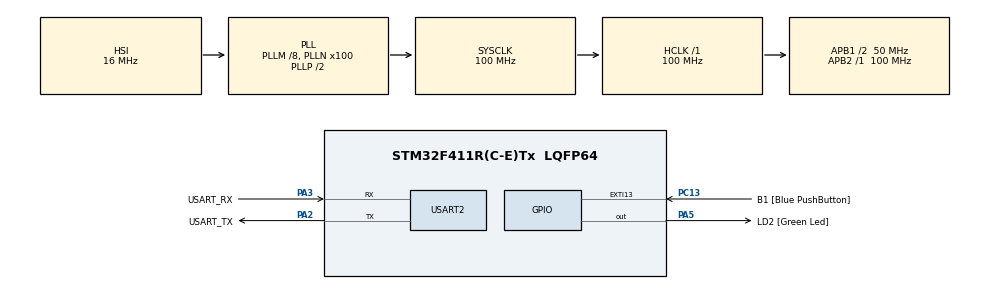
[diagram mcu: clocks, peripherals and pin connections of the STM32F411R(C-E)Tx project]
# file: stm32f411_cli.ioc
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ADC1.Channel-0\#ChannelRegularConversion=ADC_CHANNEL_TEMPSENSOR
ADC1.ContinuousConvMode=ENABLE
ADC1.DMAContinuousRequests=ENABLE
ADC1.InjNumberOfConversion=0
ADC1.NbrOfConversion=1
ADC1.NbrOfConversionFlag=1
ADC1.Rank-0\#ChannelRegularConversion=1
ADC1.SamplingTime-0\#ChannelRegularConversion=ADC_SAMPLETIME_480CYCLES
ADC1.ScanConvMode=ENABLE
ADC1.master=1
Dma.ADC1.0.Direction=DMA_PERIPH_TO_MEMORY
Dma.ADC1.0.FIFOMode=DMA_FIFOMODE_DISABLE
Dma.ADC1.0.Instance=DMA2_Stream0
Dma.ADC1.0.MemDataAlignment=DMA_MDATAALIGN_HALFWORD
Dma.ADC1.0.MemInc=DMA_MINC_ENABLE
Dma.ADC1.0.Mode=DMA_CIRCULAR
Dma.ADC1.0.PeriphDataAlignment=DMA_PDATAALIGN_HALFWORD
Dma.ADC1.0.PeriphInc=DMA_PINC_DISABLE
Dma.ADC1.0.Priority=DMA_PRIORITY_LOW
Dma.Request0=ADC1
FREERTOS.Tasks01=defaultTask,24,512,StartDefaultTask,As weak,NULL,Dynamic,NULL,NULL;myTask02,8,256,ledSystemTask,As weak,NULL,Dynamic,NULL,NULL;myTask03,8,256,tempSystemTask,As weak,NULL,Dynamic,NULL,NULL;myTask04,8,512,monitorSystemTask,As weak,NULL,Dynamic,NULL,NULL
Mcu.Family=STM32F4
Mcu.Name=STM32F411R(C-E)Tx
Mcu.Package=LQFP64
NVIC.DMA2_Stream0_IRQn=true\:5\:0\:false\:false\:true\:true\:false\:true\:true
NVIC.EXTI15_10_IRQn=true\:5\:0\:false\:false\:true\:true\:true\:true\:true
NVIC.PriorityGroup=NVIC_PRIORITYGROUP_4
NVIC.TIM1_UP_TIM10_IRQn=true\:15\:0\:false\:false\:true\:false\:false\:true\:true
NVIC.TimeBase=TIM1_UP_TIM10_IRQn
NVIC.TimeBaseIP=TIM10
NVIC.USART2_IRQn=true\:5\:0\:false\:false\:true\:true\:true\:true\:true
PA13.GPIO_Label=TMS
PA13.Mode=Serial_Wire
PA13.Signal=SYS_JTMS-SWDIO
PA14.GPIO_Label=TCK
PA14.Mode=Serial_Wire
PA14.Signal=SYS_JTCK-SWCLK
PA2.GPIO_Label=USART_TX
PA2.Mode=Asynchronous
PA2.Signal=USART2_TX
PA3.GPIO_Label=USART_RX
PA3.Mode=Asynchronous
PA3.Signal=USART2_RX
PA5.GPIO_Label=LD2 [Green Led]
PA5.Signal=GPIO_Output
PB3.GPIO_Label=SWO
PB3.Signal=SYS_JTDO-SWO
PC13-ANTI_TAMP.GPIO_Label=B1 [Blue PushButton]
PC13-ANTI_TAMP.GPIO_ModeDefaultEXTI=GPIO_MODE_IT_FALLING
PC13-ANTI_TAMP.Signal=GPXTI13
PC14-OSC32_IN.Mode=LSE-External-Oscillator
PC14-OSC32_IN.Signal=RCC_OSC32_IN
PC15-OSC32_OUT.Mode=LSE-External-Oscillator
PC15-OSC32_OUT.Signal=RCC_OSC32_OUT
PH0\ -\ OSC_IN.Mode=HSE-External-Clock-Source
PH0\ -\ OSC_IN.Signal=RCC_OSC_IN
PH1\ -\ OSC_OUT.Mode=HSE-External-Clock-Source
PH1\ -\ OSC_OUT.Signal=RCC_OSC_OUT
ProjectManager.HeapSize=0x200
ProjectManager.StackSize=0x400
ProjectManager.TargetToolchain=CMake
RCC.48MHZClocksFreq_Value=50000000
RCC.AHBFreq_Value=100000000
RCC.APB1CLKDivider=RCC_HCLK_DIV2
RCC.APB1Freq_Value=50000000
RCC.APB1TimFreq_Value=100000000
RCC.APB2Freq_Value=100000000
RCC.APB2TimFreq_Value=100000000
RCC.CortexFreq_Value=100000000
RCC.FLatency-AdvancedSettings=FLASH_LATENCY_3
RCC.HCLKFreq_Value=100000000
RCC.HSE_VALUE=8000000
RCC.HSI_VALUE=16000000
RCC.PLLM=8
RCC.PLLN=100
RCC.SYSCLKFreq_VALUE=100000000
RCC.SYSCLKSource=RCC_SYSCLKSOURCE_PLLCLK
RCC.VCOOutputFreq_Value=200000000
USART2.VirtualMode=VM_ASYNC
VP_ADC1_TempSens_Input.Mode=IN-TempSens
VP_ADC1_Vref_Input.Mode=IN-Vrefint
VP_FREERTOS_VS_CMSIS_V2.Mode=CMSIS_V2
VP_SYS_VS_tim10.Mode=TIM10
board=NUCLEO-F411RE

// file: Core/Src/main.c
/* USER CODE BEGIN Header */
/**
  ******************************************************************************
  * @file           : main.c
  * @brief          : Main program body
  ******************************************************************************
  * @attention
  *
  * Copyright (c) 2026 STMicroelectronics.
  * All rights reserved.
  *
  * This software is licensed under terms that can be found in the LICENSE file
  * in the root directory of this software component.
  * If no LICENSE file comes with this software, it is provided AS-IS.
  *
  ******************************************************************************
  */
/* USER CODE END Header */
#include "main.h"
#include "cmsis_os.h"
#include "adc.h"
#include "dma.h"
#include "usart.h"
#include "gpio.h"

void SystemClock_Config(void);
void MX_FREERTOS_Init(void);

int main(void)
{

  /* MCU Configuration--------------------------------------------------------*/

  /* Reset of all peripherals, Initializes the Flash interface and the Systick. */
  HAL_Init();

  /* Configure the system clock */
  SystemClock_Config();

  /* Initialize all configured peripherals */
  MX_GPIO_Init();
  MX_DMA_Init();
  MX_USART2_UART_Init();
  MX_ADC1_Init();

  /* Init scheduler */
  osKernelInitialize();  /* Call init function for freertos objects (in cmsis_os2.c) */
  MX_FREERTOS_Init();

  /* Start scheduler */
  osKernelStart();

  /* We should never get here as control is now taken by the scheduler */

  /* Infinite loop */
  while (1)
  {

  }
}

void SystemClock_Config(void)
{
  RCC_OscInitTypeDef RCC_OscInitStruct = {0};
  RCC_ClkInitTypeDef RCC_ClkInitStruct = {0};

  /** Configure the main internal regulator output voltage
  */
  __HAL_RCC_PWR_CLK_ENABLE();
  __HAL_PWR_VOLTAGESCALING_CONFIG(PWR_REGULATOR_VOLTAGE_SCALE1);

  /** Initializes the RCC Oscillators according to the specified parameters
  * in the RCC_OscInitTypeDef structure.
  */
  RCC_OscInitStruct.OscillatorType = RCC_OSCILLATORTYPE_HSI;
  RCC_OscInitStruct.HSIState = RCC_HSI_ON;
  RCC_OscInitStruct.HSICalibrationValue = RCC_HSICALIBRATION_DEFAULT;
  RCC_OscInitStruct.PLL.PLLState = RCC_PLL_ON;
  RCC_OscInitStruct.PLL.PLLSource = RCC_PLLSOURCE_HSI;
  RCC_OscInitStruct.PLL.PLLM = 8;
  RCC_OscInitStruct.PLL.PLLN = 100;
  RCC_OscInitStruct.PLL.PLLP = RCC_PLLP_DIV2;
  RCC_OscInitStruct.PLL.PLLQ = 4;
  if (HAL_RCC_OscConfig(&RCC_OscInitStruct) != HAL_OK)
  {
    Error_Handler();
  }

  /** Initializes the CPU, AHB and APB buses clocks
  */
  RCC_ClkInitStruct.ClockType = RCC_CLOCKTYPE_HCLK|RCC_CLOCKTYPE_SYSCLK
                              |RCC_CLOCKTYPE_PCLK1|RCC_CLOCKTYPE_PCLK2;
  RCC_ClkInitStruct.SYSCLKSource = RCC_SYSCLKSOURCE_PLLCLK;
  RCC_ClkInitStruct.AHBCLKDivider = RCC_SYSCLK_DIV1;
  RCC_ClkInitStruct.APB1CLKDivider = RCC_HCLK_DIV2;
  RCC_ClkInitStruct.APB2CLKDivider = RCC_HCLK_DIV1;

  if (HAL_RCC_ClockConfig(&RCC_ClkInitStruct, FLASH_LATENCY_3) != HAL_OK)
  {
    Error_Handler();
  }
}

void HAL_TIM_PeriodElapsedCallback(TIM_HandleTypeDef *htim)
{
  if (htim->Instance == TIM10)
  {
    HAL_IncTick();
  }
}

void Error_Handler(void)
{
  __disable_irq();
  while (1)
  {
  }
}

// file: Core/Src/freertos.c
/* USER CODE BEGIN Header */
/**
  ******************************************************************************
  * File Name          : freertos.c
  * Description        : Code for freertos applications
  ******************************************************************************
  * @attention
  *
  * Copyright (c) 2026 STMicroelectronics.
  * All rights reserved.
  *
  * This software is licensed under terms that can be found in the LICENSE file
  * in the root directory of this software component.
  * If no LICENSE file comes with this software, it is provided AS-IS.
  *
  ******************************************************************************
  */
/* USER CODE END Header */

#include "FreeRTOS.h"
#include "task.h"
#include "main.h"
#include "cmsis_os.h"

/* Definitions for defaultTask */
osThreadId_t defaultTaskHandle;
const osThreadAttr_t defaultTask_attributes = {
  .name = "defaultTask",
  .stack_size = 512 * 4,
  .priority = (osPriority_t) osPriorityNormal,
};
/* Definitions for myTask02 */
osThreadId_t myTask02Handle;
const osThreadAttr_t myTask02_attributes = {
  .name = "myTask02",
  .stack_size = 256 * 4,
  .priority = (osPriority_t) osPriorityLow,
};
/* Definitions for myTask03 */
osThreadId_t myTask03Handle;
const osThreadAttr_t myTask03_attributes = {
  .name = "myTask03",
  .stack_size = 256 * 4,
  .priority = (osPriority_t) osPriorityLow,
};
/* Definitions for myTask04 */
osThreadId_t myTask04Handle;
const osThreadAttr_t myTask04_attributes = {
  .name = "myTask04",
  .stack_size = 512 * 4,
  .priority = (osPriority_t) osPriorityLow,
};

void StartDefaultTask(void *argument);
void ledSystemTask(void *argument);
void tempSystemTask(void *argument);
void monitorSystemTask(void *argument);

void MX_FREERTOS_Init(void); /* (MISRA C 2004 rule 8.1) */

void MX_FREERTOS_Init(void) {

  /* Create the thread(s) */
  /* creation of defaultTask */
  defaultTaskHandle = osThreadNew(StartDefaultTask, NULL, &defaultTask_attributes);

  /* creation of myTask02 */
  myTask02Handle = osThreadNew(ledSystemTask, NULL, &myTask02_attributes);

  /* creation of myTask03 */
  myTask03Handle = osThreadNew(tempSystemTask, NULL, &myTask03_attributes);

  /* creation of myTask04 */
  myTask04Handle = osThreadNew(monitorSystemTask, NULL, &myTask04_attributes);

}

__weak void StartDefaultTask(void *argument)
{
  /* USER CODE BEGIN StartDefaultTask */
  // 기본 생성된 루프 대신 우리의 애플리케이션 메인 함수를 실행합니다.

  // apMain() 내부에서 while(1)을 돌기 때문에 여기까지 코드가 내려오지 않습니다.
  // 만약 루프가 종료된다면 현재 태스크를 조용히 삭제합니다.
  osThreadTerminate(NULL);
  /* USER CODE END StartDefaultTask */
}

__weak void ledSystemTask(void *argument)
{
  for(;;)
  {
    osDelay(1);
  }
}

__weak void tempSystemTask(void *argument)
{
  for(;;)
  {
    osDelay(1);
  }
}

__weak void monitorSystemTask(void *argument)
{
  for(;;)
  {
    osDelay(1);
  }
}
